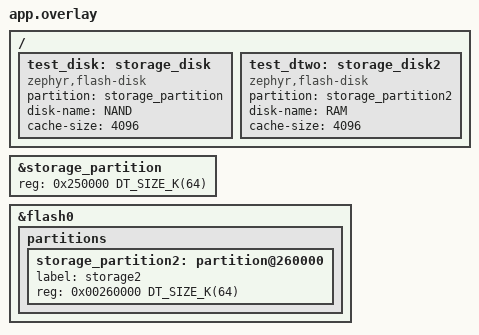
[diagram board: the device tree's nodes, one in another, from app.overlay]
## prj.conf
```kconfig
CONFIG_FILE_SYSTEM=y
CONFIG_FAT_FILESYSTEM_ELM=y

CONFIG_FILE_SYSTEM_MKFS=y
CONFIG_FS_FATFS_MOUNT_MKFS=y

# when select CONFIG_FAT_FILESYSTEM_ELM, DISK_ACCESS is auto selected by KConfig
# CONFIG_DISK_ACCESS=y

# must open CONFIG_DISK_DRIVER_FLASH, 
# otherwise fat fs mount failed
CONFIG_DISK_DRIVER_FLASH=y

CONFIG_LOG=y
# CONFIG_LOG_DEFAULT_LEVEL=4

CONFIG_FLASH=y

#
# CONFIG_FLASH_MAP=y

# fix: Stack overflow, default=1024
CONFIG_MAIN_STACK_SIZE=4096

# fix: --- 33 messages dropped ---
# 切换到立即模式避免消息丢失（性能较低）
CONFIG_LOG_MODE_IMMEDIATE=y

# 或者优化延迟模式配置
# CONFIG_LOG_MODE_DEFERRED=y
# CONFIG_LOG_BUFFER_SIZE=4096  # 增加缓冲区大小


# 设置zfsdio模块的日志级别为ERROR  (not work, compile error)
# CONFIG_LOG_LEVEL_zfsdio=1
# CONFIG_zfsdio_LOG_LEVEL=1
# CONFIG_LOG_LEVEL_disk=1
# CONFIG_LOG_LEVEL_flashdisk=1
# CONFIG_LOG_LEVEL_flash_ameba=1

# error: FLASHDISK_LOG_LEVEL (defined at subsys/logging/Kconfig.template.log_config:28) is assigned in a configuration file, but is not directly user-configurable (has no prompt). 
# CONFIG_FLASHDISK_LOG_LEVEL=1

# error: FLASH_LOG_LEVEL (defined at subsys/logging/Kconfig.template.log_config:28) is assigned in a configuration file, but is not directly user-configurable (has no prompt). 
# CONFIG_FLASH_LOG_LEVEL=1
```

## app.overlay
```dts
/*
 * Copyright (c) 2022 Nordic Semiconductor ASA
 *
 * SPDX-License-Identifier: Apache-2.0
 */


&storage_partition {
	reg = <0x250000 DT_SIZE_K(64)>;
};


&flash0 {
	partitions {
		storage_partition2: partition@260000 {
			label = "storage2";
			reg = <0x00260000 DT_SIZE_K(64)>;
		};
	};	
};

/ {
	test_disk: storage_disk {
		compatible = "zephyr,flash-disk";
		partition = <&storage_partition>;
		disk-name = "NAND";
		cache-size = <4096>;
	};

	test_dtwo: storage_disk2 {
		compatible = "zephyr,flash-disk";
		partition = <&storage_partition2>;
		disk-name = "RAM";
		cache-size = <4096>;
	};	
};
```

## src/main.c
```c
/*
 * Copyright (c) 2024 Realtek Semiconductor Corp.
 *
 * SPDX-License-Identifier: Apache-2.0
 */

#include <stdio.h>
#include <zephyr/logging/log.h>
#include <zephyr/fs/fs.h>
#include <zephyr/kernel.h>  // for k_msleep()

#include <ff.h>
// #include "os_wrapper.h"

#if 1
#if defined(CONFIG_DISK_DRIVER_FLASH)
#define DISK_NAME DT_PROP(DT_NODELABEL(test_disk), disk_name)
#define DISK_NAME2 DT_PROP(DT_NODELABEL(test_dtwo), disk_name)
#else
#error "Failed to select DISK access type"
#endif
#else
#define DISK_NAME "NAND"
#endif

#define FATFS_MNTP	"/"DISK_NAME":"
#define TEST_FILE	FATFS_MNTP"/testfile.txt"
// #define TEST_DIR	FATFS_MNTP"/testdir"
// #define TEST_DIR_FILE	FATFS_MNTP"/testdir/test2.txt"

#define FATFS_MNTP2	"/"DISK_NAME2":"
#define TEST_FILE2	FATFS_MNTP2"/test2.txt"

#include <zephyr/logging/log.h>
// LOG_MODULE_DECLARE(fs, CONFIG_FS_LOG_LEVEL);
LOG_MODULE_REGISTER(fatmain);

/* FatFs work area */
static FATFS fat_fs;

/* mounting info */
static struct fs_mount_t fatfs_mnt = {
	.type = FS_FATFS,
	.mnt_point = FATFS_MNTP,
	.fs_data = &fat_fs,
};

static struct fs_mount_t fatfs_mnt2 = {
	.type = FS_FATFS,
	.mnt_point = FATFS_MNTP2,
	.fs_data = &fat_fs,
};

void fatfs_test(struct fs_mount_t* pfatfs_mnt, char* test_file, char* test_str)
{
	int ret;
	struct fs_file_t file;
	char read_buff[128];
	ssize_t brw;
	// const char test_str[] = "Hello, FatFS on Flash!";
	size_t sz = strlen(test_str);

	LOG_INF("start to mount fatfs");
	ret = fs_mount(pfatfs_mnt);
	if (ret < 0) {
		LOG_INF("FAT file system mounting failed, [%d]\n", ret);
		goto err_ret;
	} else {
		LOG_INF("FAT file system mounting successfully\n");
	}

	LOG_INF("start to fs_file_t_init");
	fs_file_t_init(&file);
	LOG_INF("start to fs_open");
	ret = fs_open(&file, test_file, FS_O_CREATE | FS_O_RDWR);
	if (ret != 0) {
		LOG_INF("Error opening file: %s, (%d)\n", test_file, ret);
		goto err_unmount;
	} else {
		LOG_INF("open [%s] successfully\n", test_file);
	}

	// write
	LOG_INF("start to fs_write");
	ret = fs_write(&file, test_str, strlen(test_str));
	if (ret < 0) {
		LOG_INF("Error writing to file: %d\n", ret);
	}

	if (ret < strlen(test_str)) {
		LOG_INF("Unable to complete write. Volume full.\n");
	}
	LOG_INF("write date [%s] to file %s successfully. len:%d\n", test_str, test_file, ret);

	// read
	(void)fs_seek(&file, 0, FS_SEEK_SET);
	brw = fs_read(&file, read_buff, sz);
	if (brw < 0) {
		LOG_INF("Failed reading file [%zd]\n", brw);
		fs_close(&file);
		goto err_close;
	}

	read_buff[brw] = 0;

	if (strcmp(test_str, read_buff)) {
		LOG_INF("Error - Data read does not match data written\n");
		LOG_INF("Data read:\"%s\"\n\n", read_buff);
	} else {
		LOG_INF("Data read successfully. [%s]\n", read_buff);
	}

err_close:
	ret = fs_close(&file);
	if (ret != 0) {
		LOG_INF("Error closing file: %d\n", ret);
	} else {
		LOG_INF("close %s successfully\n", test_file);
	}

err_unmount:
#if 1
	ret = fs_unmount(pfatfs_mnt);
	if (ret < 0) {
		LOG_INF("Error unmount FAT file system [%d]\n", ret);
	} else {
		LOG_INF("unmount FAT file system successfully\n");
	}
#endif

err_ret:
	return 1;
}


int main(void)
{
	k_msleep(1000);
	LOG_INF("run fatfs example\n");

	const char test_str[] = "Hello, FatFS on Flash!";
	const char test_str2[] = "Good, FatFS2 on Flash!";

	fatfs_test(&fatfs_mnt2, TEST_FILE2, test_str2);
	fatfs_test(&fatfs_mnt, TEST_FILE, test_str);

	return 1;
}
```
